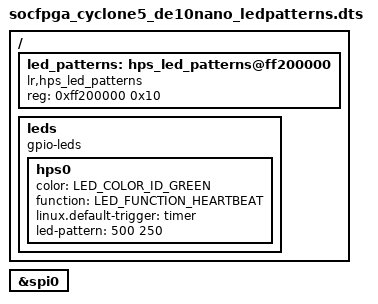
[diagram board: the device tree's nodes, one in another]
#include "socfpga_cyclone5_de0_nano_soc.dtsi"
#include <dt-bindings/leds/common.h>

/ {

    // HPS_LED_Patterns component, from Platform Designer
    led_patterns: hps_led_patterns@ff200000 {
        compatible = "lr,hps_led_patterns";
        reg = <0xff200000 0x10>;
    };

    // GPIO LED override
    leds {
        compatible = "gpio-leds";
        hps0 {
            color = <LED_COLOR_ID_GREEN>;
            function = LED_FUNCTION_HEARTBEAT;
            linux.default-trigger = "timer";
            led-pattern = <500 250>;
        };
    };

};

&spi0 {
    status = "okay";
};
